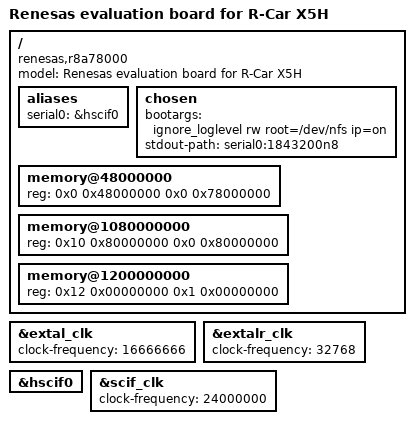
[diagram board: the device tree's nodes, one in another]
// SPDX-License-Identifier: GPL-2.0
/*
 * Device Tree Source for the R-Car X5H board
 *
 * Copyright (C) 2023 Renesas Electronics Corp.
 */

/dts-v1/;
#include "r8a78000.dtsi"

/ {
	model = "Renesas evaluation board for R-Car X5H";
	compatible = "renesas,r8a78000";

	aliases {
		serial0 = &hscif0;
	};

	chosen {
		bootargs = "ignore_loglevel rw root=/dev/nfs ip=on";
		stdout-path = "serial0:1843200n8";
	};

	memory@48000000 {
		device_type = "memory";
		/* first 128MB is reserved for secure area. */
		reg = <0x0 0x48000000 0x0 0x78000000>;
	};

	memory@1080000000 {
		device_type = "memory";
		reg = <0x10 0x80000000 0x0 0x80000000>;
	};

	memory@1200000000 {
		device_type = "memory";
		reg = <0x12 0x00000000 0x1 0x00000000>;
	};

/* Exclude the last 24GiB of SDRAM due to virtual platform limitation */
#if 0
	memory@1400000000 {
		device_type = "memory";
		reg = <0x14 0x00000000 0x1 0x00000000>;
	};

	memory@1600000000 {
		device_type = "memory";
		reg = <0x16 0x00000000 0x1 0x00000000>;
	};

	memory@1800000000 {
		device_type = "memory";
		reg = <0x18 0x00000000 0x1 0x00000000>;
	};

	memory@1a00000000 {
		device_type = "memory";
		reg = <0x1a 0x00000000 0x1 0x00000000>;
	};

	memory@1c00000000 {
		device_type = "memory";
		reg = <0x1c 0x00000000 0x1 0x00000000>;
	};

	memory@1e00000000 {
		device_type = "memory";
		reg = <0x1e 0x00000000 0x1 0x00000000>;
	};
#endif

};

&extal_clk {
	clock-frequency = <16666666>;
};

&extalr_clk {
	clock-frequency = <32768>;
};

&hscif0 {
	status = "okay";
};

&scif_clk {
	clock-frequency = <24000000>;
};
